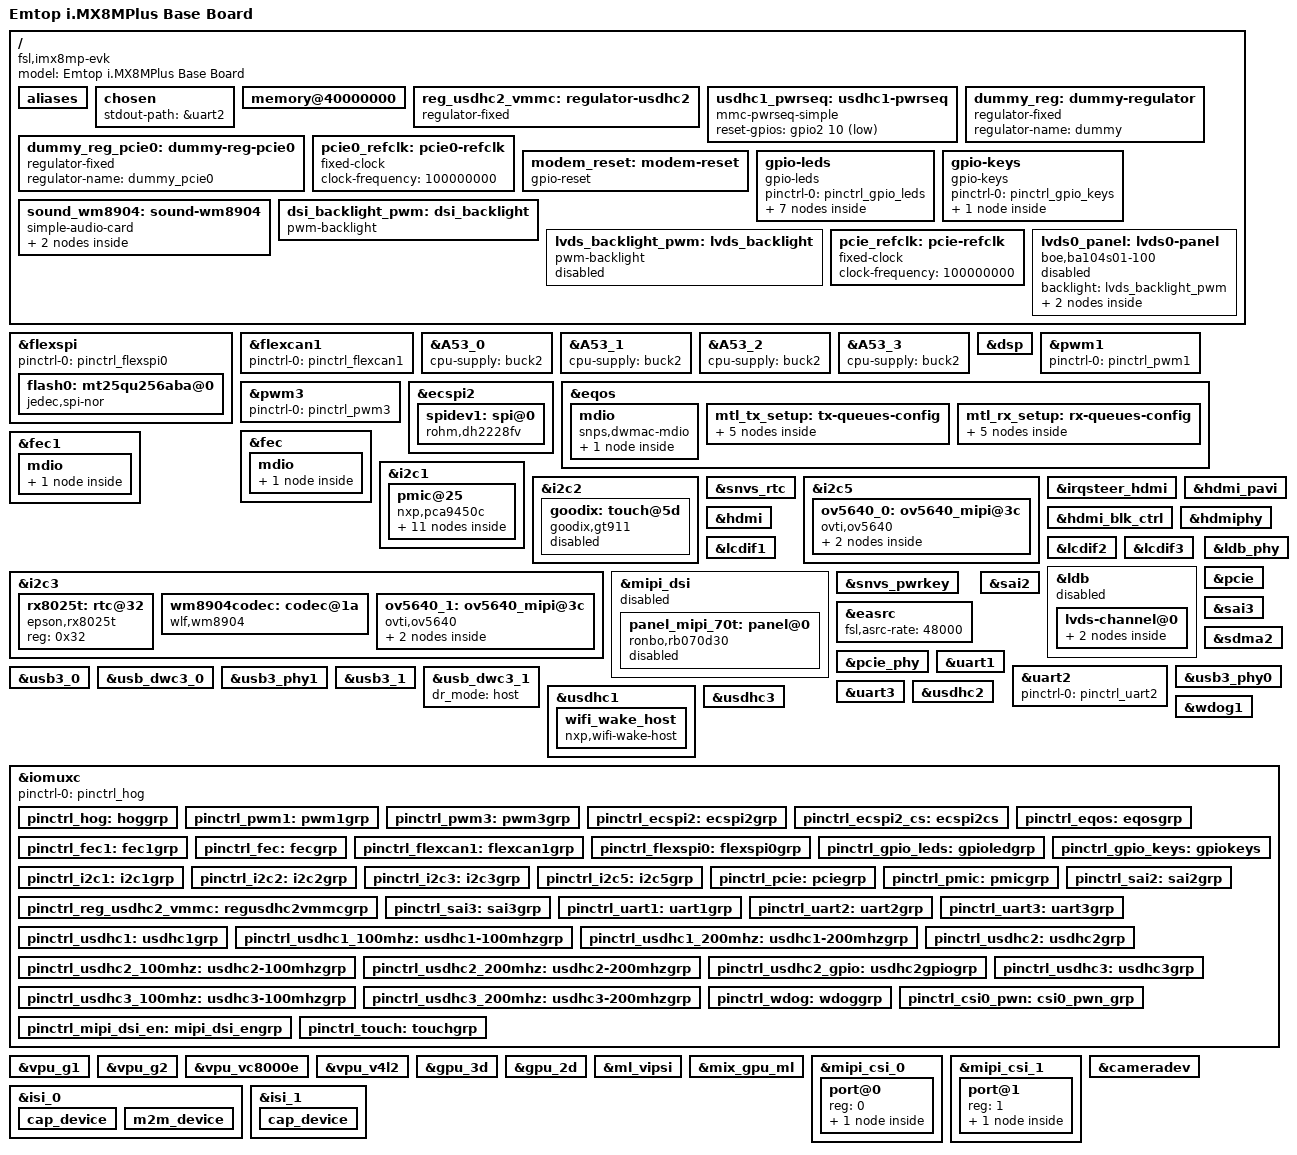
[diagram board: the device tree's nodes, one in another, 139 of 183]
// SPDX-License-Identifier: (GPL-2.0+ OR MIT)
/*
 * Copyright 2022 Emtop
 */

/dts-v1/;

#include <dt-bindings/phy/phy-imx8-pcie.h>
#include <dt-bindings/usb/pd.h>
#include "imx8mp.dtsi"

/ {
	model = "Emtop i.MX8MPlus Base Board";
	compatible = "fsl,imx8mp-evk", "fsl,imx8mp";

	aliases {
		rtc0 = &rx8025t;
		rtc1 = &snvs_rtc;
	};

	chosen {
		stdout-path = &uart2;
	};

	memory@40000000 {
		device_type = "memory";
		reg = <0x0 0x40000000 0 0xc0000000>,
		      <0x1 0x00000000 0 0xc0000000>;
	};

	reg_usdhc2_vmmc: regulator-usdhc2 {
		compatible = "regulator-fixed";
		pinctrl-names = "default";
		pinctrl-0 = <&pinctrl_reg_usdhc2_vmmc>;
		regulator-name = "VSD_3V3";
		regulator-min-microvolt = <3300000>;
		regulator-max-microvolt = <3300000>;
		gpio = <&gpio2 19 GPIO_ACTIVE_HIGH>;
		enable-active-high;
	};

	usdhc1_pwrseq: usdhc1-pwrseq {
		compatible = "mmc-pwrseq-simple";
		reset-gpios = <&gpio2 10 GPIO_ACTIVE_LOW>;
	};

	dummy_reg: dummy-regulator {
		compatible = "regulator-fixed";
		regulator-name = "dummy";
	};

	dummy_reg_pcie0: dummy-reg-pcie0 {
		compatible = "regulator-fixed";
		regulator-name = "dummy_pcie0";
	};

	pcie0_refclk: pcie0-refclk {
		compatible = "fixed-clock";
		#clock-cells = <0>;
		clock-frequency = <100000000>;
	};

	modem_reset: modem-reset {
		compatible = "gpio-reset";
		reset-gpios = <&gpio2 6 GPIO_ACTIVE_LOW>;
		reset-delay-us = <2000>;
		reset-post-delay-ms = <40>;
		#reset-cells = <0>;
	};

	gpio-leds {
		compatible = "gpio-leds";
		pinctrl-names = "default";
		pinctrl-0 = <&pinctrl_gpio_leds>;

		sys {
			label = "sys";
			gpios = <&gpio3 16 GPIO_ACTIVE_HIGH>;
			linux,default-trigger = "heartbeat";
		};

		gsm_pwrsel {
			label = "gsm_pwrsel";
			gpios = <&gpio4 0 GPIO_ACTIVE_HIGH>;
		};

		gsm_pwren {
			label = "gsm_pwren";
			gpios = <&gpio4 20 GPIO_ACTIVE_HIGH>;
		};

		gsm_reset {
			label = "gsm_reset";
			gpios = <&gpio3 14 GPIO_ACTIVE_HIGH>;
		};

		usb1_pwren {
			label = "usb1_pwren";
			gpios = <&gpio1 7 GPIO_ACTIVE_HIGH>;
			default-state = "on";
		};

		usb2hub_pwren {
			label = "usb2hub_pwren";
			gpios = <&gpio1 15 GPIO_ACTIVE_HIGH>;
			default-state = "on";
		};

		lvds_blten {
			label = "lvds_blen";
			gpios = <&gpio1 13 GPIO_ACTIVE_HIGH>;
			default-state = "on";
		};
	};

	gpio-keys {
		compatible = "gpio-keys";
		pinctrl-names = "default";
		pinctrl-0 = <&pinctrl_gpio_keys>;

		s1 {
			label = "S1";
			gpios = <&gpio2 11 GPIO_ACTIVE_LOW>;
			wakeup-source;
			linux,code = <BTN_0>;
		};
	};

	sound_wm8904: sound-wm8904 {
		compatible = "simple-audio-card";
		#sound-dai-cells = <0>;
		simple-audio-card,bitclock-master = <&dailink_master>;
		simple-audio-card,format = "i2s";
		simple-audio-card,frame-master = <&dailink_master>;
		simple-audio-card,name = "imx8mp-wm8904";
		simple-audio-card,routing =
			"Headphone Jack", "HPOUTL",
			"Headphone Jack", "HPOUTR",
			"IN2L", "Line In Jack",
			"IN2R", "Line In Jack",
			"Headphone Jack", "MICBIAS",
			"IN1L", "Headphone Jack";
		simple-audio-card,widgets =
			"Microphone", "Headphone Jack",
			"Headphone", "Headphone Jack",
			"Line", "Line In Jack";

		dailink_master: simple-audio-card,codec {
			sound-dai = <&wm8904codec>;
			clocks = <&audio_blk_ctrl IMX8MP_CLK_AUDIO_BLK_CTRL_SAI3_MCLK1>;
		};

		simple-audio-card,cpu {
			sound-dai = <&sai3>;
		};
	};

	dsi_backlight_pwm: dsi_backlight {
		compatible = "pwm-backlight";
		pwms = <&pwm1 0 1250 0>;
		status = "okay";

		brightness-levels = <0 1 2 3 4 5 6 7 8 9 10 11 12 13 14 15 16 17 18 19 20 21 22 23 24 25 26 27 28 29 30 31 32 33 34 35 36 37 38 39 40 41 42 43 44 45 46 47 48 49 50 51 52 53 54 55 56 57 58 59 60 61 62 63 64 65 66 67 68 69 70 71 72 73 74 75 76 77 78 79 80 81 82 83 84 85 86 87 88 89 90 91 92 93 94 95 96 97 98 99 100 101 102 103 104 105 106 107 108 109 110 111 112 113 114 115 116 117 118 119 120 121 122 123 124 125 126 127 128 129 130 131 132 133 134 135 136 137 138 139 140 141 142 143 144 145 146 147 148 149 150 151 152 153 154 155 156 157 158 159 160 161 162 163 164 165 166 167 168 169 170 171 172 173 174 175 176 177 178 179 180 181 182 183 184 185 186 187 188 189 190 191 192 193 194 195 196 197 198 199 200 201 202 203 204 205 206 207 208 209 210 211 212 213 214 215 216 217 218 219 220 221 222 223 224 225 226 227 228 229 230 231 232 233 234 235 236 237 238 239 240 241 242 243 244 245 246 247 248 249 250 251 252 253 254 255>;
		default-brightness-level = <200>;
	};

	lvds_backlight_pwm: lvds_backlight {
		compatible = "pwm-backlight";
		pwms = <&pwm3 0 1250 0>;
		status = "disabled";

		brightness-levels = <0 1 2 3 4 5 6 7 8 9 10 11 12 13 14 15 16 17 18 19 20 21 22 23 24 25 26 27 28 29 30 31 32 33 34 35 36 37 38 39 40 41 42 43 44 45 46 47 48 49 50 51 52 53 54 55 56 57 58 59 60 61 62 63 64 65 66 67 68 69 70 71 72 73 74 75 76 77 78 79 80 81 82 83 84 85 86 87 88 89 90 91 92 93 94 95 96 97 98 99 100 101 102 103 104 105 106 107 108 109 110 111 112 113 114 115 116 117 118 119 120 121 122 123 124 125 126 127 128 129 130 131 132 133 134 135 136 137 138 139 140 141 142 143 144 145 146 147 148 149 150 151 152 153 154 155 156 157 158 159 160 161 162 163 164 165 166 167 168 169 170 171 172 173 174 175 176 177 178 179 180 181 182 183 184 185 186 187 188 189 190 191 192 193 194 195 196 197 198 199 200 201 202 203 204 205 206 207 208 209 210 211 212 213 214 215 216 217 218 219 220 221 222 223 224 225 226 227 228 229 230 231 232 233 234 235 236 237 238 239 240 241 242 243 244 245 246 247 248 249 250 251 252 253 254 255>;
		default-brightness-level = <200>;
	};

	pcie_refclk: pcie-refclk {
		compatible = "fixed-clock";
		#clock-cells = <0>;
		clock-frequency = <100000000>;
	};

	lvds0_panel: lvds0-panel {
		compatible = "boe,ba104s01-100";
		backlight = <&lvds_backlight_pwm>;
		status = "disabled";

		port {
			panel_lvds_in: endpoint {
				remote-endpoint = <&lvds_out>;
			};
		};
	};
};

&flexspi {
	pinctrl-names = "default";
	pinctrl-0 = <&pinctrl_flexspi0>;
	status = "okay";

	flash0: mt25qu256aba@0 {
		reg = <0>;
		#address-cells = <1>;
		#size-cells = <1>;
		compatible = "jedec,spi-nor";
		spi-max-frequency = <80000000>;
		spi-tx-bus-width = <1>;
		spi-rx-bus-width = <4>;
	};
};

&flexcan1 {
	pinctrl-names = "default";
	pinctrl-0 = <&pinctrl_flexcan1>;
	status = "okay";
};

&A53_0 {
	cpu-supply = <&buck2>;
};

&A53_1 {
	cpu-supply = <&buck2>;
};

&A53_2 {
	cpu-supply = <&buck2>;
};

&A53_3 {
	cpu-supply = <&buck2>;
};

&dsp {
	status = "okay";
};

&pwm1 {
	pinctrl-names = "default";
	pinctrl-0 = <&pinctrl_pwm1>;
	status = "okay";
};

&pwm3 {
	pinctrl-names = "default";
	pinctrl-0 = <&pinctrl_pwm3>;
	status = "okay";
};

&ecspi2 {
	#address-cells = <1>;
	#size-cells = <0>;
	fsl,spi-num-chipselects = <1>;
	pinctrl-names = "default";
	pinctrl-0 = <&pinctrl_ecspi2 &pinctrl_ecspi2_cs>;
	cs-gpios = <&gpio5 13 GPIO_ACTIVE_LOW>;
	status = "okay";

	spidev1: spi@0 {
		reg = <0>;
		compatible = "rohm,dh2228fv";
		spi-max-frequency = <500000>;
	};
};

&eqos {
	pinctrl-names = "default";
	pinctrl-0 = <&pinctrl_eqos>;
	phy-mode = "rgmii-id";
	phy-handle = <&ethphy0>;
	snps,force_thresh_dma_mode;
	snps,mtl-tx-config = <&mtl_tx_setup>;
	snps,mtl-rx-config = <&mtl_rx_setup>;
	status = "okay";

	mdio {
		compatible = "snps,dwmac-mdio";
		#address-cells = <1>;
		#size-cells = <0>;

		ethphy0: ethernet-phy@4 {
			compatible = "ethernet-phy-ieee802.3-c22";
			reg = <4>;
			eee-broken-1000t;
			reset-gpios = <&gpio1 11 GPIO_ACTIVE_LOW>;
			reset-assert-us = <10000>;
			reset-deassert-us = <80000>;
			realtek,clkout-disable;
		};
	};

	mtl_tx_setup: tx-queues-config {
		snps,tx-queues-to-use = <5>;
		snps,tx-sched-sp;
		queue0 {
			snps,dcb-algorithm;
			snps,priority = <0x1>;
		};
		queue1 {
			snps,dcb-algorithm;
			snps,priority = <0x2>;
		};
		queue2 {
			snps,dcb-algorithm;
			snps,priority = <0x4>;
		};
		queue3 {
			snps,dcb-algorithm;
			snps,priority = <0x8>;
		};
		queue4 {
			snps,dcb-algorithm;
			snps,priority = <0xf0>;
		};
	};
	mtl_rx_setup: rx-queues-config {
		snps,rx-queues-to-use = <5>;
		snps,rx-sched-sp;
		queue0 {
			snps,dcb-algorithm;
			snps,priority = <0x1>;
			snps,map-to-dma-channel = <0>;
		};
		queue1 {
			snps,dcb-algorithm;
			snps,priority = <0x2>;
			snps,map-to-dma-channel = <1>;
		};
		queue2 {
			snps,dcb-algorithm;
			snps,priority = <0x4>;
			snps,map-to-dma-channel = <2>;
		};
		queue3 {
			snps,dcb-algorithm;
			snps,priority = <0x8>;
			snps,map-to-dma-channel = <3>;
		};
		queue4 {
			snps,dcb-algorithm;
			snps,priority = <0xf0>;
			snps,map-to-dma-channel = <4>;
		};
	};
};

&fec {
	pinctrl-names = "default";
	pinctrl-0 = <&pinctrl_fec>;
	phy-mode = "rgmii-id";
	phy-handle = <&ethphy1>;
	fsl,magic-packet;
	status = "okay";

	mdio {
		#address-cells = <1>;
		#size-cells = <0>;

		ethphy1: ethernet-phy@6 {
			compatible = "ethernet-phy-ieee802.3-c22";
			reg = <6>;
			eee-broken-1000t;
			reset-gpios = <&gpio4 2 GPIO_ACTIVE_LOW>;
			reset-assert-us = <10000>;
			reset-deassert-us = <80000>;
			realtek,clkout-disable;
		};
	};
};

&fec1 {
pinctrl-names = "default";
pinctrl-0 = <&pinctrl_fec1>;
phy-mode = "rgmii-id";
phy-handle = <&ethphy0>;
fsl,magic-packet;
status = "okay";
mdio {
#address-cells = <1>;
#size-cells = <0>;
ethphy0: ethernet-phy@7 {
compatible = "ethernet-phy-ieee802.3-c22";
reg = <7>;
            };
       };
};

&i2c1 {
	clock-frequency = <400000>;
	pinctrl-names = "default";
	pinctrl-0 = <&pinctrl_i2c1>;
	status = "okay";

	pmic@25 {
		compatible = "nxp,pca9450c";
		reg = <0x25>;
		pinctrl-names = "default";
		pinctrl-0 = <&pinctrl_pmic>;
		interrupt-parent = <&gpio1>;
		interrupts = <3 IRQ_TYPE_LEVEL_LOW>;

		regulators {
			buck1: BUCK1 {
				regulator-name = "BUCK1";
				regulator-min-microvolt = <600000>;
				regulator-max-microvolt = <2187500>;
				regulator-boot-on;
				regulator-always-on;
				regulator-ramp-delay = <3125>;
			};

			buck2: BUCK2 {
				regulator-name = "BUCK2";
				regulator-min-microvolt = <600000>;
				regulator-max-microvolt = <2187500>;
				regulator-boot-on;
				regulator-always-on;
				regulator-ramp-delay = <3125>;
				nxp,dvs-run-voltage = <950000>;
				nxp,dvs-standby-voltage = <850000>;
			};

			buck4: BUCK4{
				regulator-name = "BUCK4";
				regulator-min-microvolt = <600000>;
				regulator-max-microvolt = <3400000>;
				regulator-boot-on;
				regulator-always-on;
			};

			buck5: BUCK5{
				regulator-name = "BUCK5";
				regulator-min-microvolt = <600000>;
				regulator-max-microvolt = <3400000>;
				regulator-boot-on;
				regulator-always-on;
			};

			buck6: BUCK6 {
				regulator-name = "BUCK6";
				regulator-min-microvolt = <600000>;
				regulator-max-microvolt = <3400000>;
				regulator-boot-on;
				regulator-always-on;
			};

			ldo1: LDO1 {
				regulator-name = "LDO1";
				regulator-min-microvolt = <1600000>;
				regulator-max-microvolt = <3300000>;
				regulator-boot-on;
				regulator-always-on;
			};

			ldo2: LDO2 {
				regulator-name = "LDO2";
				regulator-min-microvolt = <800000>;
				regulator-max-microvolt = <1150000>;
				regulator-boot-on;
				regulator-always-on;
			};

			ldo3: LDO3 {
				regulator-name = "LDO3";
				regulator-min-microvolt = <800000>;
				regulator-max-microvolt = <3300000>;
				regulator-boot-on;
				regulator-always-on;
			};

			ldo4: LDO4 {
				regulator-name = "LDO4";
				regulator-min-microvolt = <800000>;
				regulator-max-microvolt = <3300000>;
				regulator-boot-on;
				regulator-always-on;
			};

			ldo5: LDO5 {
				regulator-name = "LDO5";
				regulator-min-microvolt = <1800000>;
				regulator-max-microvolt = <3300000>;
				regulator-boot-on;
				regulator-always-on;
			};
		};
	};
};

&i2c2 {
	clock-frequency = <100000>;
	pinctrl-names = "default";
	pinctrl-0 = <&pinctrl_i2c2>;
	status = "okay";

	goodix: touch@5d {
		compatible = "goodix,gt911";
		reg = <0x5d>;
		pinctrl-names = "default";
		pinctrl-0 = <&pinctrl_touch>;
		interrupt-parent = <&gpio1>;
		interrupts = <12 IRQ_TYPE_EDGE_FALLING>;
		irq-gpios = <&gpio1 12 GPIO_ACTIVE_HIGH>;
		reset-gpios = <&gpio1 14 GPIO_ACTIVE_LOW>;
		touchscreen-inverted-x;
		touchscreen-inverted-y;
		status = "disabled";
	};
};

&snvs_rtc {
	status = "okay";
};

&i2c3 {
	clock-frequency = <400000>;
	pinctrl-names = "default";
	pinctrl-0 = <&pinctrl_i2c3>;
	status = "okay";

	rx8025t: rtc@32 {
		compatible = "epson,rx8025t";
		reg = <0x32>;
	};

	wm8904codec: codec@1a {
		compatible = "wlf,wm8904";
		#sound-dai-cells = <0>;
		reg = <0x1a>;
		clocks = <&audio_blk_ctrl IMX8MP_CLK_AUDIO_BLK_CTRL_SAI3_MCLK1>;
		clock-names = "mclk";
		DCVDD-supply = <&buck5>;
		DBVDD-supply = <&buck4>;
		AVDD-supply = <&buck5>;
		CPVDD-supply = <&buck5>;
		MICVDD-supply = <&buck4>;
		/*
		wlf,shared-lrclk;
		wlf,hp-cfg = <3 2 3>;
		wlf,gpio-cfg = <1 3>;
		*/
	};

	ov5640_1: ov5640_mipi@3c {
		compatible = "ovti,ov5640";
		reg = <0x3c>;
		pinctrl-names = "default";
		pinctrl-0 = <&pinctrl_csi0_pwn>;
		clocks = <&clk IMX8MP_CLK_IPP_DO_CLKO2>;
		clock-names = "xclk";
		assigned-clocks = <&clk IMX8MP_CLK_IPP_DO_CLKO2>;
		assigned-clock-parents = <&clk IMX8MP_CLK_24M>;
		assigned-clock-rates = <24000000>;
		csi_id = <0>;
		powerdown-gpios = <&gpio3 20 GPIO_ACTIVE_LOW>;
		mclk = <24000000>;
		mclk_source = <0>;
		mipi_csi;
		status = "okay";

		port {
			ov5640_mipi_1_ep: endpoint {
				remote-endpoint = <&mipi_csi1_ep>;
				data-lanes = <1 2>;
				clock-lanes = <0>;
			};
		};
	};
};

&i2c5 {
	pinctrl-names = "default";
	pinctrl-0 = <&pinctrl_i2c5>;
	clock-frequency = <100000>;
	status = "okay";

	ov5640_0: ov5640_mipi@3c {
		compatible = "ovti,ov5640";
		reg = <0x3c>;
		pinctrl-names = "default";
		/*
		pinctrl-0 = <&pinctrl_csi0_pwn>;
		*/
		powerdown-gpios = <&gpio3 20 GPIO_ACTIVE_LOW>;
		clocks = <&clk IMX8MP_CLK_IPP_DO_CLKO2>;
		clock-names = "xclk";
		assigned-clocks = <&clk IMX8MP_CLK_IPP_DO_CLKO2>;
		assigned-clock-parents = <&clk IMX8MP_CLK_24M>;
		assigned-clock-rates = <24000000>;
		csi_id = <0>;
		mclk = <24000000>;
		mclk_source = <0>;
		mipi_csi;
		status = "okay";

		port {
			ov5640_mipi_0_ep: endpoint {
				remote-endpoint = <&mipi_csi0_ep>;
				data-lanes = <1 2>;
				clock-lanes = <0>;
			};
		};
	};
};

&irqsteer_hdmi {
	status = "okay";
};

&hdmi_blk_ctrl {
	status = "okay";
};

&hdmi_pavi {
	status = "okay";
};

&hdmi {
	status = "okay";
};

&hdmiphy {
	status = "okay";
};

&lcdif1 {
	status = "okay";
};

&lcdif2 {
	status = "okay";
};

&lcdif3 {
	status = "okay";

	thres-low  = <1 2>;             /* (FIFO * 1 / 2) */
	thres-high = <3 4>;             /* (FIFO * 3 / 4) */
};

&ldb {
	status = "disabled";

	lvds-channel@0 {
		fsl,data-mapping = "jeida";
		fsl,data-width = <24>;
		status = "okay";

		port@1 {
			reg = <1>;

			lvds_out: endpoint {
				remote-endpoint = <&panel_lvds_in>;
			};
		};
	};
};

&ldb_phy {
	status = "okay";
};

&mipi_dsi {
	status = "disabled";

	panel_mipi_70t: panel@0 {
		compatible = "ronbo,rb070d30";
		reg = <0>;
		pinctrl-names = "default";
		pinctrl-0 = <&pinctrl_mipi_dsi_en>;
		power-gpio = <&gpio1 5 GPIO_ACTIVE_HIGH>;
		vcc-lcd-supply = <&dummy_reg>;
		backlight = <&dsi_backlight_pwm>;
		status = "disabled";
	};
};

&snvs_pwrkey {
	status = "okay";
};

&easrc {
	fsl,asrc-rate  = <48000>;
	status = "okay";
};

&pcie {
	pinctrl-names = "default";
	pinctrl-0 = <&pinctrl_pcie>;
	reset-gpio = <&gpio5 21 GPIO_ACTIVE_LOW>;
	clocks = <&clk IMX8MP_CLK_HSIO_ROOT>,
		 <&clk IMX8MP_CLK_PCIE_ROOT>,
		 <&clk IMX8MP_CLK_HSIO_AXI>;
	clock-names = "pcie", "pcie_aux", "pcie_bus";
	assigned-clocks = <&clk IMX8MP_CLK_PCIE_AUX>;
	assigned-clock-rates = <10000000>;
	assigned-clock-parents = <&clk IMX8MP_SYS_PLL2_50M>;
	/*
	vpcie-supply = <&dummy_reg_pcie0>;
	*/
	status = "okay";
};

&pcie_phy {
	fsl,refclk-pad-mode = <IMX8_PCIE_REFCLK_PAD_OUTPUT>;
	clocks = <&pcie0_refclk>;
	clock-names = "ref";
	status = "okay";
};

&sai2 {
	#sound-dai-cells = <0>;
	pinctrl-names = "default";
	pinctrl-0 = <&pinctrl_sai2>;
	assigned-clocks = <&clk IMX8MP_CLK_SAI2>;
	assigned-clock-parents = <&clk IMX8MP_AUDIO_PLL1_OUT>;
	assigned-clock-rates = <12288000>;
	status = "okay";
};

&sai3 {
	#sound-dai-cells = <0>;
	pinctrl-names = "default";
	pinctrl-0 = <&pinctrl_sai3>;
	assigned-clocks = <&clk IMX8MP_CLK_SAI3>;
	assigned-clock-parents = <&clk IMX8MP_AUDIO_PLL1_OUT>;
	assigned-clock-rates = <12288000>;
	clocks = <&audio_blk_ctrl IMX8MP_CLK_AUDIO_BLK_CTRL_SAI3_IPG>, <&clk IMX8MP_CLK_DUMMY>,
		 <&audio_blk_ctrl IMX8MP_CLK_AUDIO_BLK_CTRL_SAI3_MCLK1>, <&clk IMX8MP_CLK_DUMMY>,
		 <&clk IMX8MP_CLK_DUMMY>;
	clock-names = "bus", "mclk0", "mclk1", "mclk2", "mclk3";
	fsl,sai-mclk-direction-output;
	status = "okay";
};

&sdma2 {
	status = "okay";
};

&uart1 { /* BT */
	pinctrl-names = "default";
	pinctrl-0 = <&pinctrl_uart1>;
	assigned-clocks = <&clk IMX8MP_CLK_UART1>;
	assigned-clock-parents = <&clk IMX8MP_SYS_PLL1_80M>;
	fsl,uart-has-rtscts;
	resets = <&modem_reset>;
	status = "okay";
};

&uart2 {
	/* console */
	pinctrl-names = "default";
	pinctrl-0 = <&pinctrl_uart2>;
	status = "okay";
};

&usb3_phy0 {
	fsl,phy-tx-vref-tune = <0xe>;
	fsl,phy-tx-preemp-amp-tune = <3>;
	fsl,phy-tx-vboost-level = <5>;
	fsl,phy-comp-dis-tune = <7>;
	fsl,pcs-tx-deemph-3p5db = <0x21>;
	fsl,phy-pcs-tx-swing-full = <0x7f>;
	status = "okay";
};

&usb3_0 {
	status = "okay";
};

&usb_dwc3_0 {
	dr_mode = "host";
	hnp-disable;
	srp-disable;
	adp-disable;
	usb-role-switch;
	role-switch-default-mode = "none";
	snps,dis-u1-entry-quirk;
	snps,dis-u2-entry-quirk;
	status = "okay";
};

&usb3_phy1 {
	fsl,phy-tx-preemp-amp-tune = <3>;
	fsl,phy-tx-vref-tune = <0xb>;
	status = "okay";
};

&usb3_1 {
	status = "okay";
};

&usb_dwc3_1 {
	dr_mode = "host";
	status = "okay";
};

&uart3 {
	pinctrl-names = "default";
	pinctrl-0 = <&pinctrl_uart3>;
	assigned-clocks = <&clk IMX8MP_CLK_UART3>;
	assigned-clock-parents = <&clk IMX8MP_SYS_PLL1_80M>;
	rts-gpios = <&gpio5 9 GPIO_ACTIVE_HIGH>;
	status = "okay";
};

&usdhc1 {
	pinctrl-names = "default", "state_100mhz", "state_200mhz";
	pinctrl-0 = <&pinctrl_usdhc1>;
	pinctrl-1 = <&pinctrl_usdhc1_100mhz>;
	pinctrl-2 = <&pinctrl_usdhc1_200mhz>;
	keep-power-in-suspend;
	non-removable;
	wakeup-source;
	mmc-pwrseq = <&usdhc1_pwrseq>;
	fsl,sdio-async-interrupt-enabled;
	status = "okay";

	wifi_wake_host {
		compatible = "nxp,wifi-wake-host";
		interrupt-parent = <&gpio2>;
		interrupts = <9 IRQ_TYPE_LEVEL_LOW>;
		interrupt-names = "host-wake";
	};
};

&usdhc2 {
	assigned-clocks = <&clk IMX8MP_CLK_USDHC2>;
	assigned-clock-rates = <400000000>;
	pinctrl-names = "default", "state_100mhz", "state_200mhz";
	pinctrl-0 = <&pinctrl_usdhc2>, <&pinctrl_usdhc2_gpio>;
	pinctrl-1 = <&pinctrl_usdhc2_100mhz>, <&pinctrl_usdhc2_gpio>;
	pinctrl-2 = <&pinctrl_usdhc2_200mhz>, <&pinctrl_usdhc2_gpio>;
	cd-gpios = <&gpio2 12 GPIO_ACTIVE_LOW>;
	vmmc-supply = <&reg_usdhc2_vmmc>;
	bus-width = <4>;
	status = "okay";
};

&usdhc3 {
	assigned-clocks = <&clk IMX8MP_CLK_USDHC3>;
	assigned-clock-rates = <400000000>;
	pinctrl-names = "default", "state_100mhz", "state_200mhz";
	pinctrl-0 = <&pinctrl_usdhc3>;
	pinctrl-1 = <&pinctrl_usdhc3_100mhz>;
	pinctrl-2 = <&pinctrl_usdhc3_200mhz>;
	bus-width = <8>;
	non-removable;
	status = "okay";
};

&wdog1 {
	pinctrl-names = "default";
	pinctrl-0 = <&pinctrl_wdog>;
	fsl,ext-reset-output;
	status = "okay";
};

&iomuxc {
	pinctrl-names = "default";
	pinctrl-0 = <&pinctrl_hog>;

	pinctrl_hog: hoggrp {
		fsl,pins = <
			MX8MP_IOMUXC_HDMI_DDC_SCL__HDMIMIX_HDMI_SCL	0x400001c3
			MX8MP_IOMUXC_HDMI_DDC_SDA__HDMIMIX_HDMI_SDA	0x400001c3
			MX8MP_IOMUXC_HDMI_HPD__HDMIMIX_HDMI_HPD		0x40000019
			MX8MP_IOMUXC_HDMI_CEC__HDMIMIX_HDMI_CEC		0x40000019
			MX8MP_IOMUXC_SAI5_RXD3__GPIO3_IO24			0x19		/* DO1 */
			MX8MP_IOMUXC_SAI5_MCLK__GPIO3_IO25			0x19		/* DO2 */
			MX8MP_IOMUXC_SAI1_TXD7__GPIO4_IO19			0x190		/* DIN1 */
			MX8MP_IOMUXC_SAI1_TXD6__GPIO4_IO18			0x190		/* DIN2 */
			/* GPIOs */
			MX8MP_IOMUXC_GPIO1_IO09__GPIO1_IO09			0x19
			MX8MP_IOMUXC_GPIO1_IO08__GPIO1_IO08			0x19
			MX8MP_IOMUXC_SAI3_RXC__GPIO4_IO29			0x19
			MX8MP_IOMUXC_SAI5_RXD0__GPIO3_IO21			0x19
			MX8MP_IOMUXC_SAI2_MCLK__GPIO4_IO27			0x19
			MX8MP_IOMUXC_ECSPI1_MISO__GPIO5_IO08		0x19
			MX8MP_IOMUXC_SAI2_RXC__GPIO4_IO22			0x19
			MX8MP_IOMUXC_SAI1_RXC__GPIO4_IO01			0x19
			MX8MP_IOMUXC_SAI5_RXFS__GPIO3_IO19			0x19
			MX8MP_IOMUXC_GPIO1_IO06__GPIO1_IO06			0x19
		>;
	};

	pinctrl_pwm1: pwm1grp {
		fsl,pins = <
			MX8MP_IOMUXC_GPIO1_IO01__PWM1_OUT	0x116		/* DSI_BK_PWM */
		>;
	};

	pinctrl_pwm3: pwm3grp {
		fsl,pins = <
			MX8MP_IOMUXC_GPIO1_IO10__PWM3_OUT	0x116		/* LVDS_BK_PWM */
		>;
	};

	pinctrl_ecspi2: ecspi2grp {
		fsl,pins = <
			MX8MP_IOMUXC_ECSPI2_SCLK__ECSPI2_SCLK		0x82
			MX8MP_IOMUXC_ECSPI2_MOSI__ECSPI2_MOSI		0x82
			MX8MP_IOMUXC_ECSPI2_MISO__ECSPI2_MISO		0x82
		>;
	};

	pinctrl_ecspi2_cs: ecspi2cs {
		fsl,pins = <
			MX8MP_IOMUXC_ECSPI2_SS0__GPIO5_IO13		0x40000
		>;
	};

	pinctrl_eqos: eqosgrp {
		fsl,pins = <
			MX8MP_IOMUXC_ENET_MDC__ENET_QOS_MDC				0x3
			MX8MP_IOMUXC_ENET_MDIO__ENET_QOS_MDIO				0x3
			MX8MP_IOMUXC_ENET_RD0__ENET_QOS_RGMII_RD0			0x91
			MX8MP_IOMUXC_ENET_RD1__ENET_QOS_RGMII_RD1			0x91
			MX8MP_IOMUXC_ENET_RD2__ENET_QOS_RGMII_RD2			0x91
			MX8MP_IOMUXC_ENET_RD3__ENET_QOS_RGMII_RD3			0x91
			MX8MP_IOMUXC_ENET_RXC__CCM_ENET_QOS_CLOCK_GENERATE_RX_CLK	0x91
			MX8MP_IOMUXC_ENET_RX_CTL__ENET_QOS_RGMII_RX_CTL			0x91
			MX8MP_IOMUXC_ENET_TD0__ENET_QOS_RGMII_TD0			0x1f
			MX8MP_IOMUXC_ENET_TD1__ENET_QOS_RGMII_TD1			0x1f
			MX8MP_IOMUXC_ENET_TD2__ENET_QOS_RGMII_TD2			0x1f
			MX8MP_IOMUXC_ENET_TD3__ENET_QOS_RGMII_TD3			0x1f
			MX8MP_IOMUXC_ENET_TX_CTL__ENET_QOS_RGMII_TX_CTL			0x1f
			MX8MP_IOMUXC_ENET_TXC__CCM_ENET_QOS_CLOCK_GENERATE_TX_CLK	0x1f
			MX8MP_IOMUXC_GPIO1_IO11__GPIO1_IO11					0x19
		>;
	};

pinctrl_fec1: fec1grp {
fsl,pins = <
MX8MM_IOMUXC_ENET_MDC_ENET1_MDC 0x3
MX8MM_IOMUXC_ENET_MDIO_ENET1_MDIO 0x3
MX8MM_IOMUXC_ENET_TD3_ENET1_RGMII_TD3 0x1f
MX8MM_IOMUXC_ENET_TD2_ENET1_RGMII_TD2 0x1f
MX8MM_IOMUXC_ENET_TD1_ENET1_RGMII_TD1 0x1f
MX8MM_IOMUXC_ENET_TD0_ENET1_RGMII_TD0 0x1f
MX8MM_IOMUXC_ENET_RD3_ENET1_RGMII_RD3 0x91
MX8MM_IOMUXC_ENET_RD2_ENET1_RGMII_RD2 0x91
MX8MM_IOMUXC_ENET_RD1_ENET1_RGMII_RD1 0x91
MX8MM_IOMUXC_ENET_RD0_ENET1_RGMII_RD0 0x91
MX8MM_IOMUXC_ENET_TXC_ENET1_RGMII_TXC 0x1f
MX8MM_IOMUXC_ENET_RXC_ENET1_RGMII_RXC 0x91
MX8MM_IOMUXC_ENET_RX_CTL_ENET1_RGMII_RX_CTL 0x91
MX8MM_IOMUXC_ENET_TX_CTL_ENET1_RGMII_TX_CTL 0x1f
MX8MM_IOMUXC_GPIO1_IO07_GPIO1_IO7 0x19
>;
};

	pinctrl_fec: fecgrp {
		fsl,pins = <
			MX8MP_IOMUXC_SAI1_RXD2__ENET1_MDC		0x3
			MX8MP_IOMUXC_SAI1_RXD3__ENET1_MDIO		0x3
			MX8MP_IOMUXC_SAI1_RXD4__ENET1_RGMII_RD0		0x91
			MX8MP_IOMUXC_SAI1_RXD5__ENET1_RGMII_RD1		0x91
			MX8MP_IOMUXC_SAI1_RXD6__ENET1_RGMII_RD2		0x91
			MX8MP_IOMUXC_SAI1_RXD7__ENET1_RGMII_RD3		0x91
			MX8MP_IOMUXC_SAI1_TXD0__ENET1_RGMII_TD0		0x1f
			MX8MP_IOMUXC_SAI1_TXD1__ENET1_RGMII_TD1		0x1f
			MX8MP_IOMUXC_SAI1_TXD2__ENET1_RGMII_TD2		0x1f
			MX8MP_IOMUXC_SAI1_TXD3__ENET1_RGMII_TD3		0x1f
			MX8MP_IOMUXC_SAI1_TXD4__ENET1_RGMII_TX_CTL	0x1f
			MX8MP_IOMUXC_SAI1_TXD5__ENET1_RGMII_TXC		0x1f
			MX8MP_IOMUXC_SAI1_TXFS__ENET1_RGMII_RX_CTL	0x1f
			MX8MP_IOMUXC_SAI1_TXC__ENET1_RGMII_RXC		0x1f
			MX8MP_IOMUXC_SAI1_RXD0__GPIO4_IO02		0x19
		>;
	};

	pinctrl_flexcan1: flexcan1grp {
		fsl,pins = <
			MX8MP_IOMUXC_SAI5_RXD2__CAN1_RX			0x154
			MX8MP_IOMUXC_SAI5_RXD1__CAN1_TX			0x154
		>;
	};

	pinctrl_flexspi0: flexspi0grp {
		fsl,pins = <
			MX8MP_IOMUXC_NAND_ALE__FLEXSPI_A_SCLK           0x1c2
			MX8MP_IOMUXC_NAND_CE0_B__FLEXSPI_A_SS0_B        0x82
			MX8MP_IOMUXC_NAND_DATA00__FLEXSPI_A_DATA00      0x82
			MX8MP_IOMUXC_NAND_DATA01__FLEXSPI_A_DATA01      0x82
			MX8MP_IOMUXC_NAND_DATA02__FLEXSPI_A_DATA02      0x82
			MX8MP_IOMUXC_NAND_DATA03__FLEXSPI_A_DATA03      0x82
		>;
	};

	pinctrl_gpio_leds: gpioledgrp {
		fsl,pins = <
			MX8MP_IOMUXC_NAND_READY_B__GPIO3_IO16	0x19
			/* 4G/5G: PWRSEL */
			MX8MP_IOMUXC_SAI1_RXFS__GPIO4_IO00		0x19
			/* 4G/5G: RESET */
			MX8MP_IOMUXC_NAND_DQS__GPIO3_IO14		0x19
			/* 4G/5G: PWREN */
			MX8MP_IOMUXC_SAI1_MCLK__GPIO4_IO20		0x19
			/* USB1: PWREN */
			MX8MP_IOMUXC_GPIO1_IO07__GPIO1_IO07		0x19
			/* USB2HUB: PWREN */
			MX8MP_IOMUXC_GPIO1_IO15__GPIO1_IO15		0x19
			/* LVDS_BK_EN */
			MX8MP_IOMUXC_GPIO1_IO13__GPIO1_IO13		0x19
		>;
	};

	pinctrl_gpio_keys: gpiokeys {
		fsl,pins = <
			MX8MP_IOMUXC_SD1_STROBE__GPIO2_IO11		0x1d9
		>;
	};

	pinctrl_i2c1: i2c1grp {
		fsl,pins = <
			MX8MP_IOMUXC_I2C1_SCL__I2C1_SCL		0x400001c2
			MX8MP_IOMUXC_I2C1_SDA__I2C1_SDA		0x400001c2
		>;
	};

	pinctrl_i2c2: i2c2grp {
		fsl,pins = <
			MX8MP_IOMUXC_I2C2_SCL__I2C2_SCL		0x400001c2
			MX8MP_IOMUXC_I2C2_SDA__I2C2_SDA		0x400001c2
		>;
	};

	pinctrl_i2c3: i2c3grp {
		fsl,pins = <
			MX8MP_IOMUXC_I2C3_SCL__I2C3_SCL		0x400001c2
			MX8MP_IOMUXC_I2C3_SDA__I2C3_SDA		0x400001c2
		>;
	};

	pinctrl_i2c5: i2c5grp {
		fsl,pins = <
			MX8MP_IOMUXC_SPDIF_TX__I2C5_SCL		0x400001c2
			MX8MP_IOMUXC_SPDIF_RX__I2C5_SDA		0x400001c2
		>;
	};

	pinctrl_pcie: pciegrp {
		fsl,pins = <
			MX8MP_IOMUXC_I2C4_SCL__PCIE_CLKREQ_B	0x61 /* open drain, pull up */
			MX8MP_IOMUXC_I2C4_SDA__GPIO5_IO21		0x1c4
		>;
	};

	pinctrl_pmic: pmicgrp {
		fsl,pins = <
			MX8MP_IOMUXC_GPIO1_IO03__GPIO1_IO03	0x000001c0
		>;
	};

	pinctrl_reg_usdhc2_vmmc: regusdhc2vmmcgrp {
		fsl,pins = <
			MX8MP_IOMUXC_SD2_RESET_B__GPIO2_IO19	0x41
		>;
	};

	pinctrl_sai2: sai2grp {
		fsl,pins = <
			MX8MP_IOMUXC_SAI2_TXC__AUDIOMIX_SAI2_TX_BCLK	0xd6
			MX8MP_IOMUXC_SAI2_TXFS__AUDIOMIX_SAI2_TX_SYNC	0xd6
			MX8MP_IOMUXC_SAI2_TXD0__AUDIOMIX_SAI2_TX_DATA00	0xd6
			MX8MP_IOMUXC_SAI2_RXD0__AUDIOMIX_SAI2_RX_DATA00	0xd6
		>;
	};

	pinctrl_sai3: sai3grp {
		fsl,pins = <
			MX8MP_IOMUXC_SAI3_TXFS__AUDIOMIX_SAI3_TX_SYNC	0xd6
			MX8MP_IOMUXC_SAI3_TXC__AUDIOMIX_SAI3_TX_BCLK	0xd6
			MX8MP_IOMUXC_SAI3_RXD__AUDIOMIX_SAI3_RX_DATA00	0xd6
			MX8MP_IOMUXC_SAI3_TXD__AUDIOMIX_SAI3_TX_DATA00	0xd6
			MX8MP_IOMUXC_SAI3_MCLK__AUDIOMIX_SAI3_MCLK	0xd6
			MX8MP_IOMUXC_SAI3_RXFS__GPIO4_IO28		0xd6
		>;
	};

	pinctrl_uart1: uart1grp {
		fsl,pins = <
			MX8MP_IOMUXC_UART1_RXD__UART1_DCE_RX	0x140
			MX8MP_IOMUXC_UART1_TXD__UART1_DCE_TX	0x140
			MX8MP_IOMUXC_UART3_RXD__UART1_DCE_CTS	0x140
			MX8MP_IOMUXC_UART3_TXD__UART1_DCE_RTS	0x140
			MX8MP_IOMUXC_GPIO1_IO00__ANAMIX_REF_CLK_32K	0x141
			MX8MP_IOMUXC_SD1_DATA4__GPIO2_IO06		0x19
		>;
	};

	pinctrl_uart2: uart2grp {
		fsl,pins = <
			MX8MP_IOMUXC_UART2_RXD__UART2_DCE_RX	0x140
			MX8MP_IOMUXC_UART2_TXD__UART2_DCE_TX	0x140
		>;
	};

	pinctrl_uart3: uart3grp {
		fsl,pins = <
			MX8MP_IOMUXC_ECSPI1_SCLK__UART3_DCE_RX		0x140
			MX8MP_IOMUXC_ECSPI1_MOSI__UART3_DCE_TX		0x140
			MX8MP_IOMUXC_ECSPI1_SS0__GPIO5_IO09			0x140
		>;
	};

	pinctrl_usdhc1: usdhc1grp {
		fsl,pins = <
			MX8MP_IOMUXC_SD1_CLK__USDHC1_CLK		0x190
			MX8MP_IOMUXC_SD1_CMD__USDHC1_CMD		0x1d0
			MX8MP_IOMUXC_SD1_DATA0__USDHC1_DATA0	0x1d0
			MX8MP_IOMUXC_SD1_DATA1__USDHC1_DATA1	0x1d0
			MX8MP_IOMUXC_SD1_DATA2__USDHC1_DATA2	0x1d0
			MX8MP_IOMUXC_SD1_DATA3__USDHC1_DATA3	0x1d0
			/* WL_REG_ON */
			MX8MP_IOMUXC_SD1_RESET_B__GPIO2_IO10	0x19
			/* WL_WAKE_HOST */
			MX8MP_IOMUXC_SD1_DATA7__GPIO2_IO09		0x1c4
		>;
	};

	pinctrl_usdhc1_100mhz: usdhc1-100mhzgrp {
		fsl,pins = <
			MX8MP_IOMUXC_SD1_CLK__USDHC1_CLK		0x194
			MX8MP_IOMUXC_SD1_CMD__USDHC1_CMD		0x1d4
			MX8MP_IOMUXC_SD1_DATA0__USDHC1_DATA0	0x1d4
			MX8MP_IOMUXC_SD1_DATA1__USDHC1_DATA1	0x1d4
			MX8MP_IOMUXC_SD1_DATA2__USDHC1_DATA2	0x1d4
			MX8MP_IOMUXC_SD1_DATA3__USDHC1_DATA3	0x1d4
			MX8MP_IOMUXC_SD1_RESET_B__GPIO2_IO10	0x19
			MX8MP_IOMUXC_SD1_DATA7__GPIO2_IO09		0x1c4
		>;
	};

	pinctrl_usdhc1_200mhz: usdhc1-200mhzgrp {
		fsl,pins = <
			MX8MP_IOMUXC_SD1_CLK__USDHC1_CLK		0x196
			MX8MP_IOMUXC_SD1_CMD__USDHC1_CMD		0x1d6
			MX8MP_IOMUXC_SD1_DATA0__USDHC1_DATA0	0x1d6
			MX8MP_IOMUXC_SD1_DATA1__USDHC1_DATA1	0x1d6
			MX8MP_IOMUXC_SD1_DATA2__USDHC1_DATA2	0x1d6
			MX8MP_IOMUXC_SD1_DATA3__USDHC1_DATA3	0x1d6
			MX8MP_IOMUXC_SD1_RESET_B__GPIO2_IO10	0x19
			MX8MP_IOMUXC_SD1_DATA7__GPIO2_IO09		0x1c4
		>;
	};

	pinctrl_usdhc2: usdhc2grp {
		fsl,pins = <
			MX8MP_IOMUXC_SD2_CLK__USDHC2_CLK	0x190
			MX8MP_IOMUXC_SD2_CMD__USDHC2_CMD	0x1d0
			MX8MP_IOMUXC_SD2_DATA0__USDHC2_DATA0	0x1d0
			MX8MP_IOMUXC_SD2_DATA1__USDHC2_DATA1	0x1d0
			MX8MP_IOMUXC_SD2_DATA2__USDHC2_DATA2	0x1d0
			MX8MP_IOMUXC_SD2_DATA3__USDHC2_DATA3	0x1d0
			MX8MP_IOMUXC_GPIO1_IO04__USDHC2_VSELECT	0xc1
		>;
	};

	pinctrl_usdhc2_100mhz: usdhc2-100mhzgrp {
		fsl,pins = <
			MX8MP_IOMUXC_SD2_CLK__USDHC2_CLK	0x194
			MX8MP_IOMUXC_SD2_CMD__USDHC2_CMD	0x1d4
			MX8MP_IOMUXC_SD2_DATA0__USDHC2_DATA0	0x1d4
			MX8MP_IOMUXC_SD2_DATA1__USDHC2_DATA1	0x1d4
			MX8MP_IOMUXC_SD2_DATA2__USDHC2_DATA2	0x1d4
			MX8MP_IOMUXC_SD2_DATA3__USDHC2_DATA3	0x1d4
			MX8MP_IOMUXC_GPIO1_IO04__USDHC2_VSELECT 0xc1
		>;
	};

	pinctrl_usdhc2_200mhz: usdhc2-200mhzgrp {
		fsl,pins = <
			MX8MP_IOMUXC_SD2_CLK__USDHC2_CLK	0x196
			MX8MP_IOMUXC_SD2_CMD__USDHC2_CMD	0x1d6
			MX8MP_IOMUXC_SD2_DATA0__USDHC2_DATA0	0x1d6
			MX8MP_IOMUXC_SD2_DATA1__USDHC2_DATA1	0x1d6
			MX8MP_IOMUXC_SD2_DATA2__USDHC2_DATA2	0x1d6
			MX8MP_IOMUXC_SD2_DATA3__USDHC2_DATA3	0x1d6
			MX8MP_IOMUXC_GPIO1_IO04__USDHC2_VSELECT 0xc1
		>;
	};

	pinctrl_usdhc2_gpio: usdhc2gpiogrp {
		fsl,pins = <
			MX8MP_IOMUXC_SD2_CD_B__GPIO2_IO12	0x1c4
		>;
	};

	pinctrl_usdhc3: usdhc3grp {
		fsl,pins = <
			MX8MP_IOMUXC_NAND_WE_B__USDHC3_CLK	0x190
			MX8MP_IOMUXC_NAND_WP_B__USDHC3_CMD	0x1d0
			MX8MP_IOMUXC_NAND_DATA04__USDHC3_DATA0	0x1d0
			MX8MP_IOMUXC_NAND_DATA05__USDHC3_DATA1	0x1d0
			MX8MP_IOMUXC_NAND_DATA06__USDHC3_DATA2	0x1d0
			MX8MP_IOMUXC_NAND_DATA07__USDHC3_DATA3	0x1d0
			MX8MP_IOMUXC_NAND_RE_B__USDHC3_DATA4	0x1d0
			MX8MP_IOMUXC_NAND_CE2_B__USDHC3_DATA5	0x1d0
			MX8MP_IOMUXC_NAND_CE3_B__USDHC3_DATA6	0x1d0
			MX8MP_IOMUXC_NAND_CLE__USDHC3_DATA7	0x1d0
			MX8MP_IOMUXC_NAND_CE1_B__USDHC3_STROBE	0x190
		>;
	};

	pinctrl_usdhc3_100mhz: usdhc3-100mhzgrp {
		fsl,pins = <
			MX8MP_IOMUXC_NAND_WE_B__USDHC3_CLK	0x194
			MX8MP_IOMUXC_NAND_WP_B__USDHC3_CMD	0x1d4
			MX8MP_IOMUXC_NAND_DATA04__USDHC3_DATA0	0x1d4
			MX8MP_IOMUXC_NAND_DATA05__USDHC3_DATA1	0x1d4
			MX8MP_IOMUXC_NAND_DATA06__USDHC3_DATA2	0x1d4
			MX8MP_IOMUXC_NAND_DATA07__USDHC3_DATA3	0x1d4
			MX8MP_IOMUXC_NAND_RE_B__USDHC3_DATA4	0x1d4
			MX8MP_IOMUXC_NAND_CE2_B__USDHC3_DATA5	0x1d4
			MX8MP_IOMUXC_NAND_CE3_B__USDHC3_DATA6	0x1d4
			MX8MP_IOMUXC_NAND_CLE__USDHC3_DATA7	0x1d4
			MX8MP_IOMUXC_NAND_CE1_B__USDHC3_STROBE	0x194
		>;
	};

	pinctrl_usdhc3_200mhz: usdhc3-200mhzgrp {
		fsl,pins = <
			MX8MP_IOMUXC_NAND_WE_B__USDHC3_CLK	0x196
			MX8MP_IOMUXC_NAND_WP_B__USDHC3_CMD	0x1d6
			MX8MP_IOMUXC_NAND_DATA04__USDHC3_DATA0	0x1d6
			MX8MP_IOMUXC_NAND_DATA05__USDHC3_DATA1	0x1d6
			MX8MP_IOMUXC_NAND_DATA06__USDHC3_DATA2	0x1d6
			MX8MP_IOMUXC_NAND_DATA07__USDHC3_DATA3	0x1d6
			MX8MP_IOMUXC_NAND_RE_B__USDHC3_DATA4	0x1d6
			MX8MP_IOMUXC_NAND_CE2_B__USDHC3_DATA5	0x1d6
			MX8MP_IOMUXC_NAND_CE3_B__USDHC3_DATA6	0x1d6
			MX8MP_IOMUXC_NAND_CLE__USDHC3_DATA7	0x1d6
			MX8MP_IOMUXC_NAND_CE1_B__USDHC3_STROBE	0x196
		>;
	};

	pinctrl_wdog: wdoggrp {
		fsl,pins = <
			MX8MP_IOMUXC_GPIO1_IO02__WDOG1_WDOG_B	0x166
		>;
	};

	pinctrl_csi0_pwn: csi0_pwn_grp {
		fsl,pins = <
			MX8MP_IOMUXC_SAI5_RXC__GPIO3_IO20		0x19
		>;
	};

	pinctrl_mipi_dsi_en: mipi_dsi_engrp {
		fsl,pins = <
			MX8MP_IOMUXC_GPIO1_IO05__GPIO1_IO05		0x19
		>;
	};

	pinctrl_touch: touchgrp {
		fsl,pins = <
			MX8MP_IOMUXC_GPIO1_IO14__GPIO1_IO14		0x19		/* CTP_RST */
			MX8MP_IOMUXC_GPIO1_IO12__GPIO1_IO12		0x19		/* CTP_INT */
		>;
	};
};

&vpu_g1 {
	status = "okay";
};

&vpu_g2 {
	status = "okay";
};

&vpu_vc8000e {
	status = "okay";
};

&vpu_v4l2 {
	status = "okay";
};

&gpu_3d {
	status = "okay";
};

&gpu_2d {
	status = "okay";
};

&ml_vipsi {
	status = "okay";
};

&mix_gpu_ml {
	status = "okay";
};

&mipi_csi_0 {
	#address-cells = <1>;
	#size-cells = <0>;
	status = "okay";

	port@0 {
		reg = <0>;
		mipi_csi0_ep: endpoint {
			remote-endpoint = <&ov5640_mipi_0_ep>;
			data-lanes = <2>;
			csis-hs-settle = <13>;
			csis-clk-settle = <2>;
			csis-wclk;
		};
	};
};

&mipi_csi_1 {
	#address-cells = <1>;
	#size-cells = <0>;
	status = "okay";

	port@1 {
		reg = <1>;
		mipi_csi1_ep: endpoint {
			remote-endpoint = <&ov5640_mipi_1_ep>;
			data-lanes = <2>;
			csis-hs-settle = <13>;
			csis-clk-settle = <2>;
			csis-wclk;
		};
	};
};

&cameradev {
	status = "okay";
};

&isi_0 {
	status = "okay";

	cap_device {
		status = "okay";
	};

	m2m_device {
		status = "okay";
	};
};

&isi_1 {
	status = "okay";

	cap_device {
		status = "okay";
	};
};
